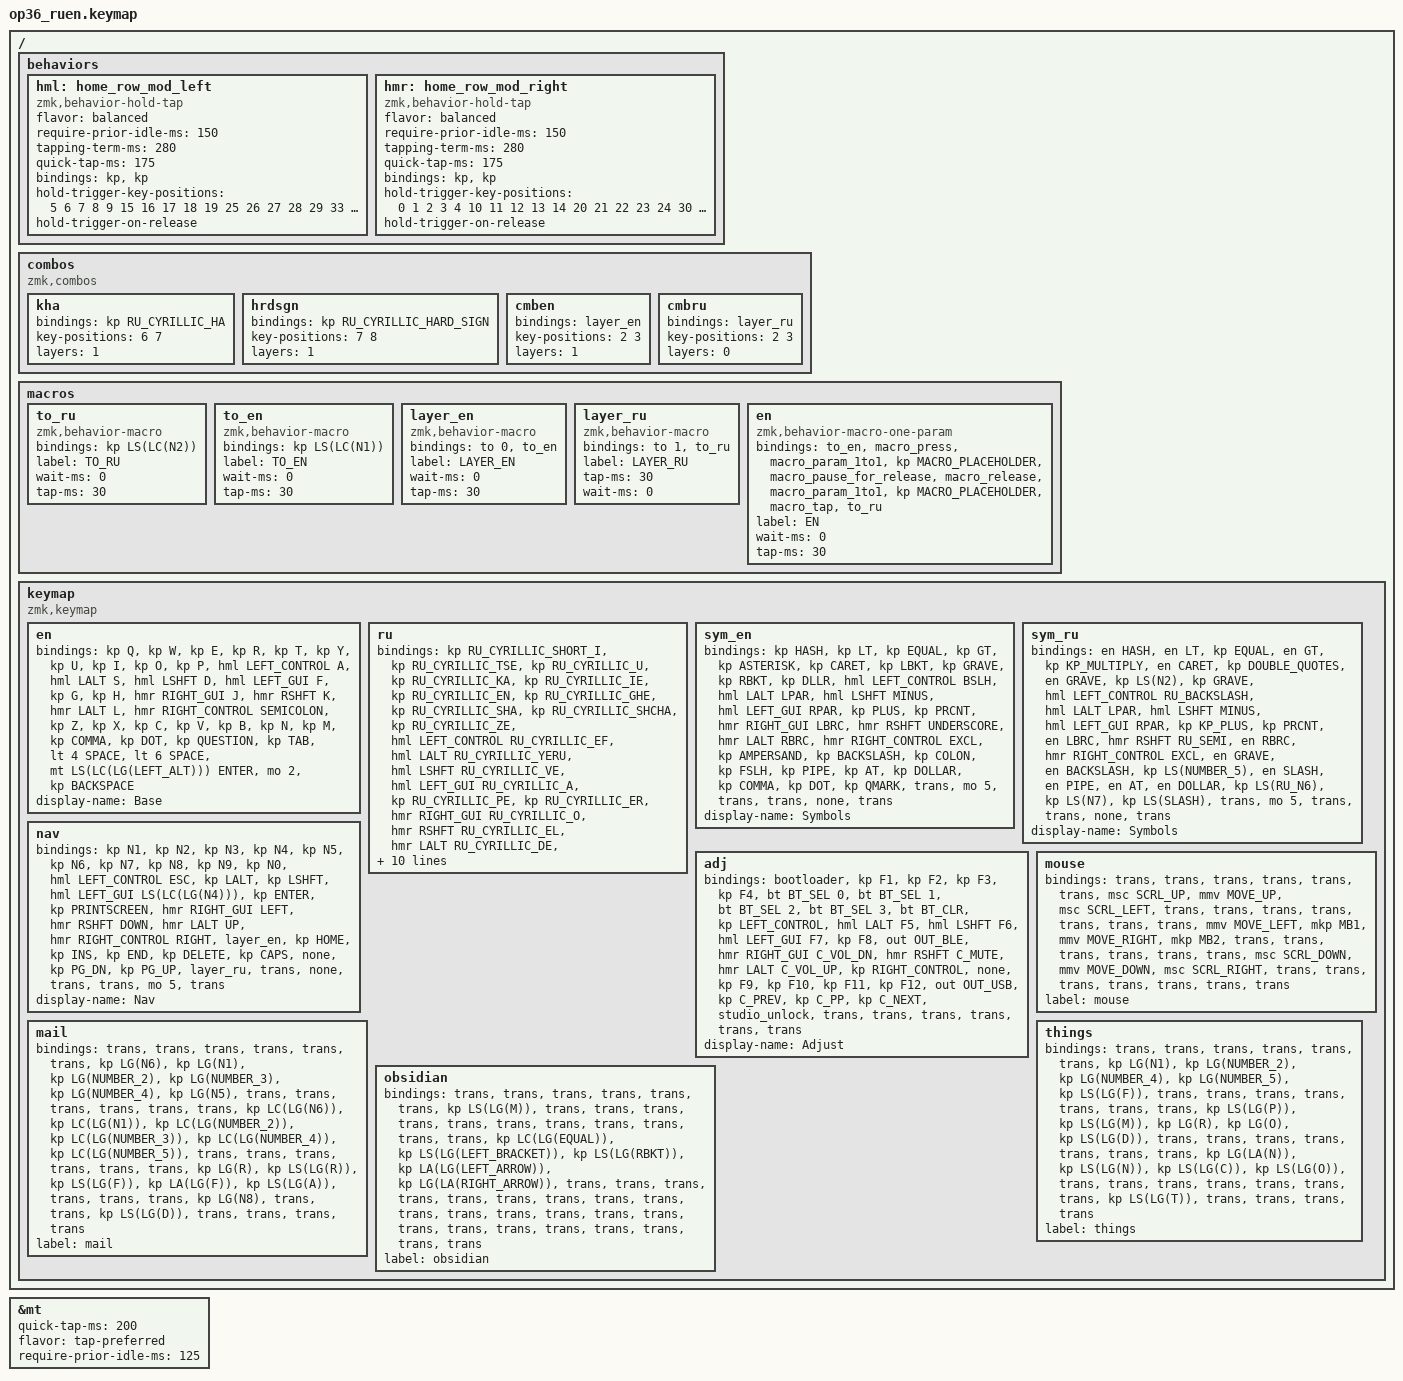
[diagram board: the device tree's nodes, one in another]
#include "keys_ru.h"
#include "keys_ru.h"
#include <behaviors.dtsi>
#include <dt-bindings/zmk/bt.h>
#include <dt-bindings/zmk/keys.h>
#include <dt-bindings/zmk/outputs.h>
#include <dt-bindings/zmk/pointing.h>

&mt {
    quick-tap-ms = <200>;
    flavor = "tap-preferred";
    require-prior-idle-ms = <125>;
};

/ {
    behaviors {
        hml: home_row_mod_left {
            compatible = "zmk,behavior-hold-tap";
            #binding-cells = <2>;
            flavor = "balanced";
            require-prior-idle-ms = <150>;
            tapping-term-ms = <280>;
            quick-tap-ms = <175>;
            bindings = <&kp>, <&kp>;

            hold-trigger-key-positions = <5 6 7 8 9 15 16 17 18 19 25 26 27 28 29 33 34 35>;
            hold-trigger-on-release;
        };

        hmr: home_row_mod_right {
            compatible = "zmk,behavior-hold-tap";
            #binding-cells = <2>;
            flavor = "balanced";
            require-prior-idle-ms = <150>;
            tapping-term-ms = <280>;
            quick-tap-ms = <175>;
            bindings = <&kp>, <&kp>;

            hold-trigger-key-positions = <0 1 2 3 4 10 11 12 13 14 20 21 22 23 24 30 31 32>;
            hold-trigger-on-release;
        };
    };

    combos {
        compatible = "zmk,combos";

        kha {
            bindings = <&kp RU_CYRILLIC_HA>;
            key-positions = <6 7>;
            layers = <1>;
        };

        hrdsgn {
            bindings = <&kp RU_CYRILLIC_HARD_SIGN>;
            key-positions = <7 8>;
            layers = <1>;
        };

        cmben {
            bindings = <&layer_en>;
            key-positions = <2 3>;
            layers = <1>;
        };

        cmbru {
            bindings = <&layer_ru>;
            key-positions = <2 3>;
            layers = <0>;
        };
    };

    macros {
        to_ru: to_ru {
            compatible = "zmk,behavior-macro";
            #binding-cells = <0>;
            bindings = <&kp LS(LC(N2))>;
            label = "TO_RU";
            wait-ms = <0>;
            tap-ms = <30>;
        };

        to_en: to_en {
            compatible = "zmk,behavior-macro";
            #binding-cells = <0>;
            bindings = <&kp LS(LC(N1))>;
            label = "TO_EN";
            wait-ms = <0>;
            tap-ms = <30>;
        };

        layer_en: layer_en {
            compatible = "zmk,behavior-macro";
            #binding-cells = <0>;
            bindings = <&to 0 &to_en>;
            label = "LAYER_EN";
            wait-ms = <0>;
            tap-ms = <30>;
        };

        layer_ru: layer_ru {
            compatible = "zmk,behavior-macro";
            #binding-cells = <0>;
            bindings = <&to 1 &to_ru>;
            label = "LAYER_RU";
            tap-ms = <30>;
            wait-ms = <0>;
        };

        en: en {
            compatible = "zmk,behavior-macro-one-param";
            #binding-cells = <1>;
            bindings =
                <&to_en>,
                <&macro_press>,
                <&macro_param_1to1 &kp MACRO_PLACEHOLDER>,
                <&macro_pause_for_release>,
                <&macro_release>,
                <&macro_param_1to1 &kp MACRO_PLACEHOLDER>,
                <&macro_tap>,
                <&to_ru>;

            label = "EN";
            wait-ms = <0>;
            tap-ms = <30>;
        };
    };

    keymap {
        compatible = "zmk,keymap";

        en {
            bindings = <
  &kp Q                &kp W        &kp E         &kp R            &kp T                                                       &kp Y  &kp U             &kp I         &kp O        &kp P
  &hml LEFT_CONTROL A  &hml LALT S  &hml LSHFT D  &hml LEFT_GUI F  &kp G                                                       &kp H  &hmr RIGHT_GUI J  &hmr RSHFT K  &hmr LALT L  &hmr RIGHT_CONTROL SEMICOLON
  &kp Z                &kp X        &kp C         &kp V            &kp B                                                       &kp N  &kp M             &kp COMMA     &kp DOT      &kp QUESTION
                                                  &kp TAB          &lt 4 SPACE  &lt 6 SPACE    &mt LS(LC(LG(LEFT_ALT))) ENTER  &mo 2  &kp BACKSPACE
            >;

            display-name = "Base";
        };

        ru {
            bindings = <
  &kp RU_CYRILLIC_SHORT_I           &kp RU_CYRILLIC_TSE         &kp RU_CYRILLIC_U          &kp RU_CYRILLIC_KA           &kp RU_CYRILLIC_IE                                                 &kp RU_CYRILLIC_EN  &kp RU_CYRILLIC_GHE           &kp RU_CYRILLIC_SHA        &kp RU_CYRILLIC_SHCHA     &kp RU_CYRILLIC_ZE
  &hml LEFT_CONTROL RU_CYRILLIC_EF  &hml LALT RU_CYRILLIC_YERU  &hml LSHFT RU_CYRILLIC_VE  &hml LEFT_GUI RU_CYRILLIC_A  &kp RU_CYRILLIC_PE                                                 &kp RU_CYRILLIC_ER  &hmr RIGHT_GUI RU_CYRILLIC_O  &hmr RSHFT RU_CYRILLIC_EL  &hmr LALT RU_CYRILLIC_DE  &hmr RIGHT_CONTROL RU_CYRILLIC_ZHE
  &kp RU_CYRILLIC_YA                &kp RU_CYRILLIC_CHE         &kp RU_CYRILLIC_ES         &kp RU_CYRILLIC_EM           &kp RU_CYRILLIC_I                                                  &kp RU_CYRILLIC_TE  &kp RU_CYRILLIC_SOFT_SIGN     &kp RU_CYRILLIC_BE         &kp RU_CYRILLIC_YU        &kp RU_CYRILLIC_E
                                                                                           &kp TAB                      &lt 4 SPACE         &lt 6 SPACE    &mt LS(LC(LG(LEFT_ALT))) ENTER  &mo 3               &kp BACKSPACE
            >;

            display-name = "Ru";
        };

        sym_en {
            bindings = <
  &kp HASH                &kp LT          &kp EQUAL         &kp GT              &kp ASTERISK                    &kp CARET  &kp LBKT             &kp GRAVE              &kp RBKT        &kp DLLR
  &hml LEFT_CONTROL BSLH  &hml LALT LPAR  &hml LSHFT MINUS  &hml LEFT_GUI RPAR  &kp PLUS                        &kp PRCNT  &hmr RIGHT_GUI LBRC  &hmr RSHFT UNDERSCORE  &hmr LALT RBRC  &hmr RIGHT_CONTROL EXCL
  &kp AMPERSAND           &kp BACKSLASH   &kp COLON         &kp FSLH            &kp PIPE                        &kp AT     &kp DOLLAR           &kp COMMA              &kp DOT         &kp QMARK
                                                            &trans              &mo 5         &trans    &trans  &none      &trans
            >;

            display-name = "Symbols";
        };

        sym_ru {
            bindings = <
  &en HASH                        &en LT          &kp EQUAL         &en GT              &kp KP_MULTIPLY                    &en CARET  &kp DOUBLE_QUOTES  &en GRAVE           &kp LS(N2)  &kp GRAVE
  &hml LEFT_CONTROL RU_BACKSLASH  &hml LALT LPAR  &hml LSHFT MINUS  &hml LEFT_GUI RPAR  &kp KP_PLUS                        &kp PRCNT  &en LBRC           &hmr RSHFT RU_SEMI  &en RBRC    &hmr RIGHT_CONTROL EXCL
  &en GRAVE                       &en BACKSLASH   &kp LS(NUMBER_5)  &en SLASH           &en PIPE                           &en AT     &en DOLLAR         &kp LS(RU_N6)       &kp LS(N7)  &kp LS(SLASH)
                                                                    &trans              &mo 5            &trans    &trans  &none      &trans
            >;

            display-name = "Symbols";
        };

        nav {
            bindings = <
  &kp N1                 &kp N2    &kp N3     &kp N4                        &kp N5                        &kp N6           &kp N7               &kp N8           &kp N9        &kp N0
  &hml LEFT_CONTROL ESC  &kp LALT  &kp LSHFT  &hml LEFT_GUI LS(LC(LG(N4)))  &kp ENTER                     &kp PRINTSCREEN  &hmr RIGHT_GUI LEFT  &hmr RSHFT DOWN  &hmr LALT UP  &hmr RIGHT_CONTROL RIGHT
  &layer_en              &kp HOME  &kp INS    &kp END                       &kp DELETE                    &kp CAPS         &none                &kp PG_DN        &kp PG_UP     &layer_ru
                                              &trans                        &none       &trans    &trans  &mo 5            &trans
            >;

            display-name = "Nav";
        };

        adj {
            bindings = <
  &bootloader       &kp F1        &kp F2         &kp F3            &kp F4                     &bt BT_SEL 0  &bt BT_SEL 1             &bt BT_SEL 2       &bt BT_SEL 3        &bt BT_CLR
  &kp LEFT_CONTROL  &hml LALT F5  &hml LSHFT F6  &hml LEFT_GUI F7  &kp F8                     &out OUT_BLE  &hmr RIGHT_GUI C_VOL_DN  &hmr RSHFT C_MUTE  &hmr LALT C_VOL_UP  &kp RIGHT_CONTROL
  &none             &kp F9        &kp F10        &kp F11           &kp F12                    &out OUT_USB  &kp C_PREV               &kp C_PP           &kp C_NEXT          &studio_unlock
                                                 &trans            &trans   &trans    &trans  &trans        &trans
            >;

            display-name = "Adjust";
        };

        mouse {
            bindings = <
  &trans  &trans  &trans  &trans  &trans                    &trans  &msc SCRL_UP    &mmv MOVE_UP    &msc SCRL_LEFT   &trans
  &trans  &trans  &trans  &trans  &trans                    &trans  &mmv MOVE_LEFT  &mkp MB1        &mmv MOVE_RIGHT  &mkp MB2
  &trans  &trans  &trans  &trans  &trans                    &trans  &msc SCRL_DOWN  &mmv MOVE_DOWN  &msc SCRL_RIGHT  &trans
                          &trans  &trans  &trans    &trans  &trans  &trans
            >;

            label = "mouse";
        };
        mail {
            bindings = <
&trans  &trans  &trans  &trans  &trans      &trans                           &kp LG(N6)      &kp LG(N1)      &kp LG(NUMBER_2)      &kp LG(NUMBER_3)      &kp LG(NUMBER_4)      &kp LG(N5)
&trans  &trans  &trans  &trans  &trans      &trans                           &kp LC(LG(N6))  &kp LC(LG(N1))  &kp LC(LG(NUMBER_2))  &kp LC(LG(NUMBER_3))  &kp LC(LG(NUMBER_4))  &kp LC(LG(NUMBER_5))
&trans  &trans  &trans  &trans  &trans      &trans                           &kp LG(R)       &kp LS(LG(R))   &kp LS(LG(F))         &kp LA(LG(F))         &kp LS(LG(A))         &trans
                &trans  &trans  &kp LG(N8)  &trans  &trans    &kp LS(LG(D))  &trans          &trans          &trans                &trans
            >;

            label = "mail";
        };

        things {
            bindings = <
&trans  &trans  &trans  &trans  &trans  &trans                           &kp LG(N1)     &kp LG(NUMBER_2)  &kp LG(NUMBER_4)  &kp LG(NUMBER_5)  &kp LS(LG(F))  &trans
&trans  &trans  &trans  &trans  &trans  &trans                           &kp LS(LG(P))  &kp LS(LG(M))     &kp LG(R)         &kp LG(O)         &kp LS(LG(D))  &trans
&trans  &trans  &trans  &trans  &trans  &trans                           &kp LG(LA(N))  &kp LS(LG(N))     &kp LS(LG(C))     &kp LS(LG(O))     &trans         &trans
                &trans  &trans  &trans  &trans  &trans    &kp LS(LG(T))  &trans         &trans            &trans            &trans
            >;

            label = "things";
        };

        obsidian {
            bindings = <
&trans  &trans  &trans  &trans  &trans  &trans                    &kp LS(LG(M))      &trans                    &trans            &trans                  &trans                   &trans
&trans  &trans  &trans  &trans  &trans  &trans                    &kp LC(LG(EQUAL))  &kp LS(LG(LEFT_BRACKET))  &kp LS(LG(RBKT))  &kp LA(LG(LEFT_ARROW))  &kp LG(LA(RIGHT_ARROW))  &trans
&trans  &trans  &trans  &trans  &trans  &trans                    &trans             &trans                    &trans            &trans                  &trans                   &trans
                &trans  &trans  &trans  &trans  &trans    &trans  &trans             &trans                    &trans            &trans
            >;

            label = "obsidian";
        };
    };
};
